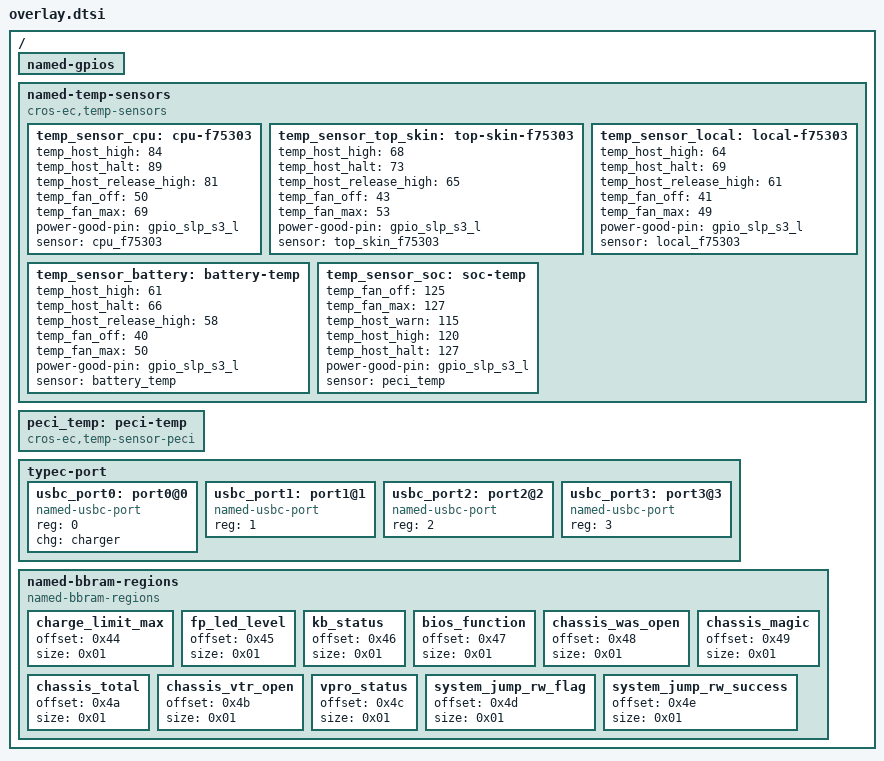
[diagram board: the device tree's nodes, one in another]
/* Copyright 2024 The ChromiumOS Authors
 * Use of this source code is governed by a BSD-style license that can be
 * found in the LICENSE file.
 */

#include <freq.h>


/ {
	named-gpios {
		/* Lotus-specific GPIO customizations */
	};

	named-temp-sensors {
		compatible = "cros-ec,temp-sensors";
		/* Q56 sensor close to cpu */
		temp_sensor_cpu: cpu-f75303 {
			temp_host_high = <84>;
			temp_host_halt = <89>;
			temp_host_release_high = <81>;
			temp_fan_off = <50>;
			temp_fan_max = <69>;
			power-good-pin = <&gpio_slp_s3_l>;
			sensor = <&cpu_f75303>;
		};
		/* Q57 sensor on top skin close to H16 */
		temp_sensor_top_skin: top-skin-f75303 {
			temp_host_high = <68>;
			temp_host_halt = <73>;
			temp_host_release_high = <65>;
			temp_fan_off = <43>;
			temp_fan_max = <53>;
			power-good-pin = <&gpio_slp_s3_l>;
			sensor = <&top_skin_f75303>;
		};
		/* U31 sensor.*/
		temp_sensor_local: local-f75303 {
			temp_host_high = <64>;
			temp_host_halt = <69>;
			temp_host_release_high = <61>;
			temp_fan_off = <41>;
			temp_fan_max = <49>;
			power-good-pin = <&gpio_slp_s3_l>;
			sensor = <&local_f75303>;
		};
		temp_sensor_battery: battery-temp {
			temp_host_high = <61>;
			temp_host_halt = <66>;
			temp_host_release_high = <58>;
			temp_fan_off = <40>;
			temp_fan_max = <50>;
			power-good-pin = <&gpio_slp_s3_l>;
			sensor = <&battery_temp>;
		};
		temp_sensor_soc: soc-temp {
			/* just read, no protection */
			temp_fan_off = <125>;
			temp_fan_max = <127>;
			temp_host_warn = <115>;
			temp_host_high = <120>;
			temp_host_halt = <127>;
			power-good-pin = <&gpio_slp_s3_l>;
			sensor = <&peci_temp>;
		};
	};

	peci_temp: peci-temp {
		compatible = "cros-ec,temp-sensor-peci";
	};

	typec-port {
		#address-cells = <1>;
		#size-cells = <0>;

		/*
		 * If the CHARGER_SINGLE_CHIP config is enabled, only
		 * one charger chip must be defined.
		 *
		 * In the Zephyer OS, the CONFIG_USB_PD_PORT_MAX_COUNT will check
		 * the device tree compatible "named-usbc-port"
		 */
		usbc_port0: port0@0 {
			compatible = "named-usbc-port";
			reg = <0>;
			chg = <&charger>;
		};
		usbc_port1: port1@1 {
			compatible = "named-usbc-port";
			reg = <1>;
		};
		usbc_port2: port2@2 {
			compatible = "named-usbc-port";
			reg = <2>;
		};
		usbc_port3: port3@3 {
			compatible = "named-usbc-port";
			reg = <3>;
		};
	};

	named-bbram-regions {
		compatible = "named-bbram-regions";

		charge_limit_max {
			offset = <0x44>;
			size = <0x01>;
		};
		fp_led_level {
			offset = <0x45>;
			size = <0x01>;
		};
		kb_status {
			offset = <0x46>;
			size = <0x01>;
		};
		bios_function {
			offset = <0x47>;
			size = <0x01>;
		};
		chassis_was_open {
			offset = <0x48>;
			size = <0x01>;
		};
		chassis_magic {
			offset = <0x49>;
			size = <0x01>;
		};
		chassis_total {
			offset = <0x4a>;
			size = <0x01>;
		};
		chassis_vtr_open {
			offset = <0x4b>;
			size = <0x01>;
		};
		vpro_status {
			offset = <0x4c>;
			size = <0x01>;
		};
		system_jump_rw_flag {
			offset = <0x4d>;
			size = <0x01>;
		};
		system_jump_rw_success {
			offset = <0x4e>;
			size = <0x01>;
		};
	};
};
